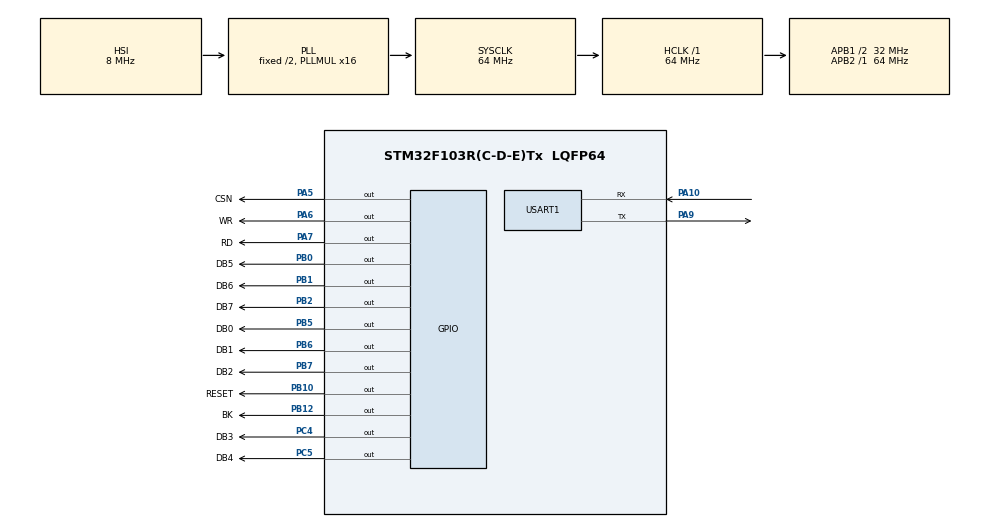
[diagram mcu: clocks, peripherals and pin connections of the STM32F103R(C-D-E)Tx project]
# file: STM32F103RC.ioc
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FREERTOS.Tasks01=defaultTask,0,128,StartDefaultTask,Default,NULL,Dynamic,NULL,NULL
Mcu.Family=STM32F1
Mcu.Name=STM32F103R(C-D-E)Tx
Mcu.Package=LQFP64
NVIC.PriorityGroup=NVIC_PRIORITYGROUP_4
PA10.Mode=Asynchronous
PA10.Signal=USART1_RX
PA13.Mode=Serial_Wire
PA13.Signal=SYS_JTMS-SWDIO
PA14.Mode=Serial_Wire
PA14.Signal=SYS_JTCK-SWCLK
PA5.GPIO_Label=CSN
PA5.Signal=GPIO_Output
PA6.GPIO_Label=WR
PA6.Signal=GPIO_Output
PA7.GPIO_Label=RD
PA7.Signal=GPIO_Output
PA9.Mode=Asynchronous
PA9.Signal=USART1_TX
PB0.GPIO_Label=DB5
PB0.Signal=GPIO_Output
PB1.GPIO_Label=DB6
PB1.Signal=GPIO_Output
PB10.GPIO_Label=RESET
PB10.Signal=GPIO_Output
PB12.GPIO_Label=BK
PB12.Signal=GPIO_Output
PB2.GPIO_Label=DB7
PB2.Signal=GPIO_Output
PB5.GPIO_Label=DB0
PB5.Signal=GPIO_Output
PB6.GPIO_Label=DB1
PB6.Signal=GPIO_Output
PB7.GPIO_Label=DB2
PB7.Signal=GPIO_Output
PC4.GPIO_Label=DB3
PC4.Signal=GPIO_Output
PC5.GPIO_Label=DB4
PC5.Signal=GPIO_Output
ProjectManager.HeapSize=0x200
ProjectManager.StackSize=0x400
ProjectManager.TargetToolchain=MDK-ARM V5.32
RCC.AHBFreq_Value=64000000
RCC.APB1CLKDivider=RCC_HCLK_DIV2
RCC.APB1Freq_Value=32000000
RCC.APB1TimFreq_Value=64000000
RCC.APB2Freq_Value=64000000
RCC.APB2TimFreq_Value=64000000
RCC.HCLKFreq_Value=64000000
RCC.PLLMUL=RCC_PLL_MUL16
RCC.SYSCLKFreq_VALUE=64000000
RCC.SYSCLKSource=RCC_SYSCLKSOURCE_PLLCLK
RCC.USBFreq_Value=64000000
TIM2.Prescaler=71
USART1.VirtualMode=VM_ASYNC
VP_FREERTOS_VS_CMSIS_V1.Mode=CMSIS_V1
VP_TIM2_VS_ClockSourceINT.Mode=Internal
board=custom

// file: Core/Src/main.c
/* USER CODE BEGIN Header */
/**
  ******************************************************************************
  * @file           : main.c
  * @brief          : Main program body
  ******************************************************************************
  * @attention
  *
  * Copyright (c) 2024 STMicroelectronics.
  * All rights reserved.
  *
  * This software is licensed under terms that can be found in the LICENSE file
  * in the root directory of this software component.
  * If no LICENSE file comes with this software, it is provided AS-IS.
  *
  ******************************************************************************
  */
/* USER CODE END Header */
#include "main.h"
#include "cmsis_os.h"
#include "tim.h"
#include "usart.h"
#include "gpio.h"

void SystemClock_Config(void);
void MX_FREERTOS_Init(void);

int main(void)
{

  /* MCU Configuration--------------------------------------------------------*/

  /* Reset of all peripherals, Initializes the Flash interface and the Systick. */
  HAL_Init();

  /* Configure the system clock */
  SystemClock_Config();

  /* Initialize all configured peripherals */
  MX_GPIO_Init();
  MX_USART1_UART_Init();
  MX_TIM2_Init();
  /* USER CODE BEGIN 2 */
    // HAL_GPIO_WritePin(BK_GPIO_Port, BK_Pin, GPIO_PIN_RESET);
    // HAL_Delay(1000);
    // HAL_GPIO_WritePin(BK_GPIO_Port, BK_Pin, GPIO_PIN_RESET);
    // HAL_Delay(1000);
    // HAL_GPIO_WritePin(BK_GPIO_Port, BK_Pin, GPIO_PIN_SET);
  /* USER CODE END 2 */

  /* Call init function for freertos objects (in freertos.c) */
  MX_FREERTOS_Init();

  /* Start scheduler */
  osKernelStart();

  /* We should never get here as control is now taken by the scheduler */
  /* Infinite loop */
  while (1)
  {

  }
}

void SystemClock_Config(void)
{
  RCC_OscInitTypeDef RCC_OscInitStruct = {0};
  RCC_ClkInitTypeDef RCC_ClkInitStruct = {0};

  /** Initializes the RCC Oscillators according to the specified parameters
  * in the RCC_OscInitTypeDef structure.
  */
  RCC_OscInitStruct.OscillatorType = RCC_OSCILLATORTYPE_HSI;
  RCC_OscInitStruct.HSIState = RCC_HSI_ON;
  RCC_OscInitStruct.HSICalibrationValue = RCC_HSICALIBRATION_DEFAULT;
  RCC_OscInitStruct.PLL.PLLState = RCC_PLL_ON;
  RCC_OscInitStruct.PLL.PLLSource = RCC_PLLSOURCE_HSI_DIV2;
  RCC_OscInitStruct.PLL.PLLMUL = RCC_PLL_MUL16;
  if (HAL_RCC_OscConfig(&RCC_OscInitStruct) != HAL_OK)
  {
    Error_Handler();
  }

  /** Initializes the CPU, AHB and APB buses clocks
  */
  RCC_ClkInitStruct.ClockType = RCC_CLOCKTYPE_HCLK|RCC_CLOCKTYPE_SYSCLK
                              |RCC_CLOCKTYPE_PCLK1|RCC_CLOCKTYPE_PCLK2;
  RCC_ClkInitStruct.SYSCLKSource = RCC_SYSCLKSOURCE_PLLCLK;
  RCC_ClkInitStruct.AHBCLKDivider = RCC_SYSCLK_DIV1;
  RCC_ClkInitStruct.APB1CLKDivider = RCC_HCLK_DIV2;
  RCC_ClkInitStruct.APB2CLKDivider = RCC_HCLK_DIV1;

  if (HAL_RCC_ClockConfig(&RCC_ClkInitStruct, FLASH_LATENCY_2) != HAL_OK)
  {
    Error_Handler();
  }
}

void Error_Handler(void)
{
  __disable_irq();
  while (1)
  {
  }
}

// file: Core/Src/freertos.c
/* USER CODE BEGIN Header */
/**
  ******************************************************************************
  * File Name          : freertos.c
  * Description        : Code for freertos applications
  ******************************************************************************
  * @attention
  *
  * Copyright (c) 2024 STMicroelectronics.
  * All rights reserved.
  *
  * This software is licensed under terms that can be found in the LICENSE file
  * in the root directory of this software component.
  * If no LICENSE file comes with this software, it is provided AS-IS.
  *
  ******************************************************************************
  */
/* USER CODE END Header */

#include "FreeRTOS.h"
#include "task.h"
#include "main.h"
#include "cmsis_os.h"

/* USER CODE BEGIN Includes */
#include "common.h"
/* USER CODE END Includes */

osThreadId defaultTaskHandle;

void StartDefaultTask(void const * argument);

void MX_FREERTOS_Init(void); /* (MISRA C 2004 rule 8.1) */

/* GetIdleTaskMemory prototype (linked to static allocation support) */
void vApplicationGetIdleTaskMemory( StaticTask_t **ppxIdleTaskTCBBuffer, StackType_t **ppxIdleTaskStackBuffer, uint32_t *pulIdleTaskStackSize );

/* USER CODE BEGIN GET_IDLE_TASK_MEMORY */
static StaticTask_t xIdleTaskTCBBuffer;
static StackType_t xIdleStack[configMINIMAL_STACK_SIZE];

void vApplicationGetIdleTaskMemory( StaticTask_t **ppxIdleTaskTCBBuffer, StackType_t **ppxIdleTaskStackBuffer, uint32_t *pulIdleTaskStackSize )
{
  *ppxIdleTaskTCBBuffer = &xIdleTaskTCBBuffer;
  *ppxIdleTaskStackBuffer = &xIdleStack[0];
  *pulIdleTaskStackSize = configMINIMAL_STACK_SIZE;
  /* place for user code */
}
/* USER CODE END GET_IDLE_TASK_MEMORY */

void MX_FREERTOS_Init(void) {

  /* Create the thread(s) */
  /* definition and creation of defaultTask */
  osThreadDef(defaultTask, StartDefaultTask, osPriorityNormal, 0, 128);
  defaultTaskHandle = osThreadCreate(osThread(defaultTask), NULL);

}

void StartDefaultTask(void const * argument)
{
  /* USER CODE BEGIN StartDefaultTask */
  uint16_t data;
  HAL_GPIO_WritePin(BK_GPIO_Port,BK_Pin,GPIO_PIN_SET);
  LCD_RST_Low();
  vTaskDelay(100);
  LCD_RST_High();
  // HAL_UART_Transmit(&huart1, (uint8_t *) "&ch", 3, 0xffff);
  vTaskDelay(100);
  lcd_init();
	vTaskDelay(100);
  lcd_fillRect(10,10,50,50, RGB_565(237, 28, 36) );

  ReadID();
	// for ( int i=0; i<255; i++ ) {
	// 	LCD_RST_Low();
	// 	vTaskDelay(100);
	// 	LCD_RST_High();
	// 	data = lcd_8080_read(i);
	// }

  printf("addr: 0x00 data: %d\n", data);

  /* Infinite loop */
  for(;;)
  {
    osDelay(1);
  }
  /* USER CODE END StartDefaultTask */
}
